# calc5_target_db register map
Vendor: Texas Instruments
Address unit: 16 bits
Registers are 32-bit, read-write, reset 0x0 unless marked. A register's access mark holds for its fields unless they carry their own. Offsets are as the file gives them; [hi:lo] are bit positions; {n}, {i} and the like mark numbered series; 'fields as' and 'values as' point back to an identical list; <NAME> marks a mode.

## DSS (part 2 of 4) — ipxact12_to_ccs_generated
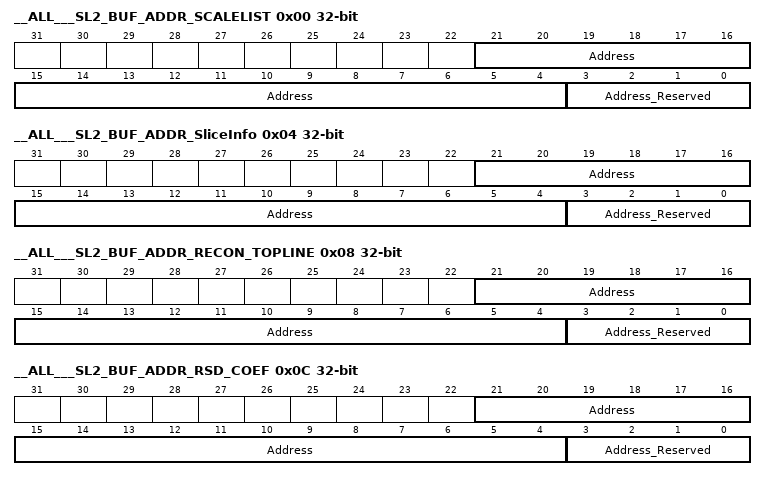
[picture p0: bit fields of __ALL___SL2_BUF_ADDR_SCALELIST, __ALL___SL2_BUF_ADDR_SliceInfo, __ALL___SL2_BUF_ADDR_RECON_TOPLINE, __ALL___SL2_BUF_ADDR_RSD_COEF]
0x00 __ALL___SL2_BUF_ADDR_SCALELIST access per field — Start Address for Scalling List Matrix same as "weight Matrix" in CALC3 (Required only in High-Profile, else don't care)
  [21:4] Address rw — 128-bit (16-byte) aligned address
  [3:0] Address_Reserved ro — Address is 128-bit (16*BitDepth) aligned
0x04 __ALL___SL2_BUF_ADDR_SliceInfo access per field
  fields as __ALL___SL2_BUF_ADDR_SCALELIST
0x08 __ALL___SL2_BUF_ADDR_RECON_TOPLINE access per field
  fields as __ALL___SL2_BUF_ADDR_SCALELIST
0x0C __ALL___SL2_BUF_ADDR_RSD_COEF access per field
  fields as __ALL___SL2_BUF_ADDR_SCALELIST
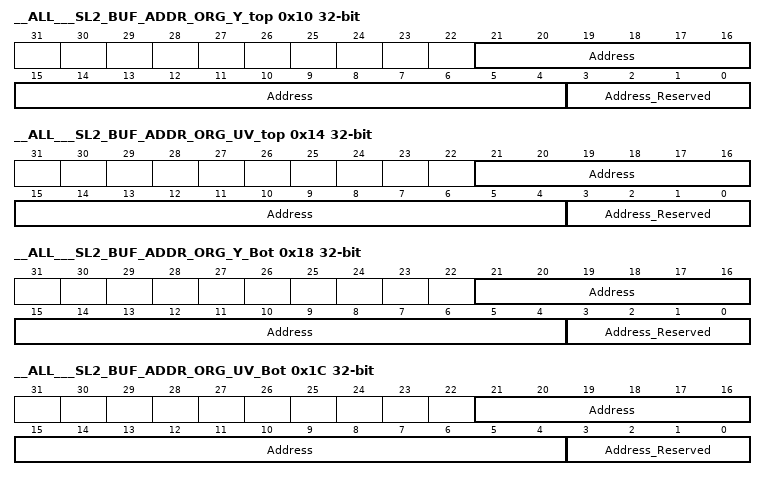
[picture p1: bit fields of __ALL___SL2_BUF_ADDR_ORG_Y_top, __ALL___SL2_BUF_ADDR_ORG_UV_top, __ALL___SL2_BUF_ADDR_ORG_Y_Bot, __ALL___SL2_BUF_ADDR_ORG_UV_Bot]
0x10 __ALL___SL2_BUF_ADDR_ORG_Y_top access per field
  fields as __ALL___SL2_BUF_ADDR_SCALELIST
0x14 __ALL___SL2_BUF_ADDR_ORG_UV_top access per field
  fields as __ALL___SL2_BUF_ADDR_SCALELIST
0x18 __ALL___SL2_BUF_ADDR_ORG_Y_Bot access per field
  fields as __ALL___SL2_BUF_ADDR_SCALELIST
0x1C __ALL___SL2_BUF_ADDR_ORG_UV_Bot access per field
  fields as __ALL___SL2_BUF_ADDR_SCALELIST
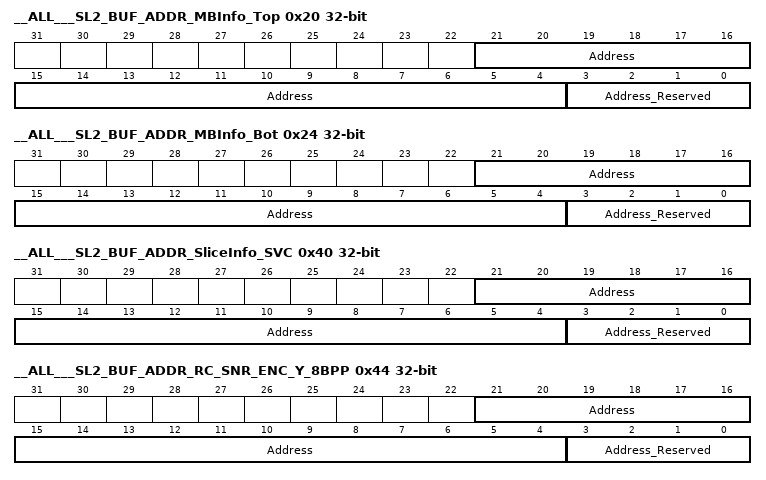
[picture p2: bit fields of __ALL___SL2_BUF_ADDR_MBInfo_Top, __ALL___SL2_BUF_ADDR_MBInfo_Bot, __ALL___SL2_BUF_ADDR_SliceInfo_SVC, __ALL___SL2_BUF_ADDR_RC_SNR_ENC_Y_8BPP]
0x20 __ALL___SL2_BUF_ADDR_MBInfo_Top access per field
  fields as __ALL___SL2_BUF_ADDR_SCALELIST
0x24 __ALL___SL2_BUF_ADDR_MBInfo_Bot access per field
  fields as __ALL___SL2_BUF_ADDR_SCALELIST
0x40 __ALL___SL2_BUF_ADDR_SliceInfo_SVC access per field — SL2 BA of SVC Extrension of Slice Info
  fields as __ALL___SL2_BUF_ADDR_SCALELIST
0x44 __ALL___SL2_BUF_ADDR_RC_SNR_ENC_Y_8BPP access per field — SL2 base address for rc luma 8bpp output for me5 from calc5
  fields as __ALL___SL2_BUF_ADDR_SCALELIST
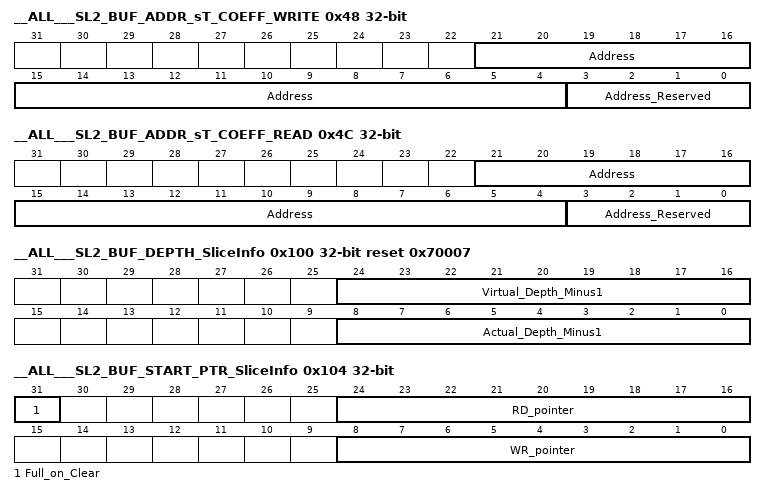
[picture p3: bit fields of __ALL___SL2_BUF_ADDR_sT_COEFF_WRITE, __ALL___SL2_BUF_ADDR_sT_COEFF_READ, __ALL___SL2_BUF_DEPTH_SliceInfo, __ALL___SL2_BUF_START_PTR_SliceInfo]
0x48 __ALL___SL2_BUF_ADDR_sT_COEFF_WRITE access per field — SL2 base address for stcoeff output from calc5
  fields as __ALL___SL2_BUF_ADDR_SCALELIST
0x4C __ALL___SL2_BUF_ADDR_sT_COEFF_READ access per field — SL2 base address for stcoeff input to calc5
  fields as __ALL___SL2_BUF_ADDR_SCALELIST
0x100 __ALL___SL2_BUF_DEPTH_SliceInfo access per field reset 0x70007 — Configures the SLiceInfo Buffer depth.
  [24:16] Virtual_Depth_Minus1 rw — Indicates the Maximum pointer difference. Virtual buffer depth < Actual buffer depth. When the pointer difference is more than the configured value the wr_bc_ready gets de-asserted.
  [8:0] Actual_Depth_Minus1 rw — Number of entries in the Buffer = 1 + Actual_buffer_depth_minus1
0x104 __ALL___SL2_BUF_START_PTR_SliceInfo access per field — Configures the Slice_Info Buffer pointers.
  [31] Full_on_Clear rw — if (WR_pointer == RD_pointer) [0] : buffer is empty [1] : buffer is full
  [24:16] RD_pointer rw — Start value of Read pointer, initialized on BC_CLR. Range: 0 to Actual_buffer_depth_minus1
  [8:0] WR_pointer rw — Start value of Write pointer, initialized on BC_CLR. Range: 0 to Actual_buffer_depth_minus1
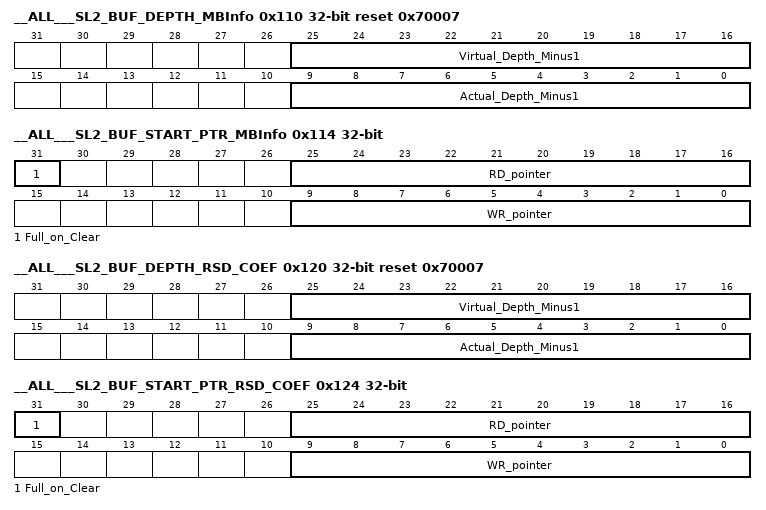
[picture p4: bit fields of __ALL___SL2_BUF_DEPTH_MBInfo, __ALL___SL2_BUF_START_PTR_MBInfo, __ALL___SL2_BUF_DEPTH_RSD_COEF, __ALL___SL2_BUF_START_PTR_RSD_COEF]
0x110 __ALL___SL2_BUF_DEPTH_MBInfo access per field reset 0x70007 — Configures the MBInfo Buffer depth.
  [25:16] Virtual_Depth_Minus1 rw — Indicates the Maximum pointer difference. Virtual buffer depth < Actual buffer depth. When the pointer difference is more than the configured value the wr_bc_ready gets de-asserted.
  [9:0] Actual_Depth_Minus1 rw — Number of entries in the Buffer = 1 + Actual_buffer_depth_minus1
0x114 __ALL___SL2_BUF_START_PTR_MBInfo access per field — Configures the MB-Info Buffer pointers.
  [31] Full_on_Clear rw — if (WR_pointer == RD_pointer) [0] : buffer is empty [1] : buffer is full
  [25:16] RD_pointer rw — Start value of Read pointer, initialized on BC_CLR. Range: 0 to Actual_buffer_depth_minus1
  [9:0] WR_pointer rw — Start value of Write pointer, initialized on BC_CLR. Range: 0 to Actual_buffer_depth_minus1
0x120 __ALL___SL2_BUF_DEPTH_RSD_COEF access per field reset 0x70007 — Configures the Residue Buffer depth.
  fields as __ALL___SL2_BUF_DEPTH_MBInfo
0x124 __ALL___SL2_BUF_START_PTR_RSD_COEF access per field — Configures the Residual Buffer pointers.
  fields as __ALL___SL2_BUF_START_PTR_MBInfo
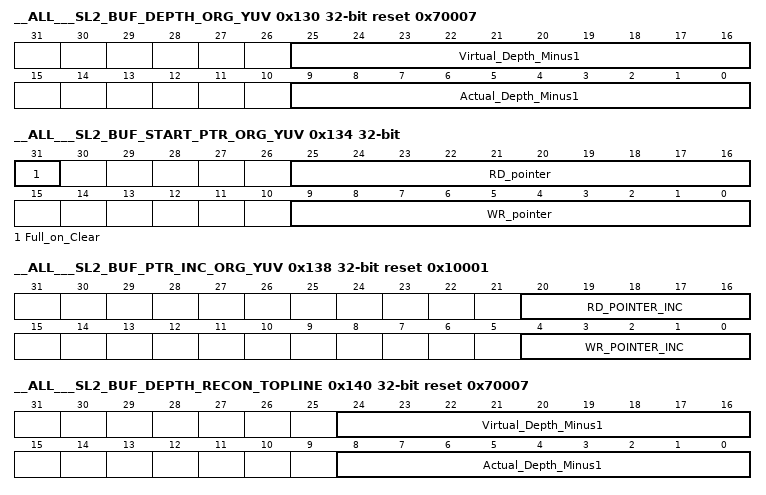
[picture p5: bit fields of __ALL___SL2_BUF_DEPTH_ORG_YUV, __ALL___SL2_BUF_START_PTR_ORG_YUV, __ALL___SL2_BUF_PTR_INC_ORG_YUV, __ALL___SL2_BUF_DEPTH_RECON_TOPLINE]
0x130 __ALL___SL2_BUF_DEPTH_ORG_YUV access per field reset 0x70007 — Configures the Original Buffer depth.
  fields as __ALL___SL2_BUF_DEPTH_MBInfo
0x134 __ALL___SL2_BUF_START_PTR_ORG_YUV access per field — Configures the Original Buffer pointers.
  fields as __ALL___SL2_BUF_START_PTR_MBInfo
0x138 __ALL___SL2_BUF_PTR_INC_ORG_YUV access per field reset 0x10001 — Configures the increment offset for buffer pointers.
  [20:16] RD_POINTER_INC ro
  [4:0] WR_POINTER_INC rw — Increment value for write pointer on wr_core_busy deassertion. Range: 0 to Actual_buffer_depth_minus1
0x140 __ALL___SL2_BUF_DEPTH_RECON_TOPLINE access per field reset 0x70007 — Configures the RefPix Buffer depth.
  fields as __ALL___SL2_BUF_DEPTH_SliceInfo
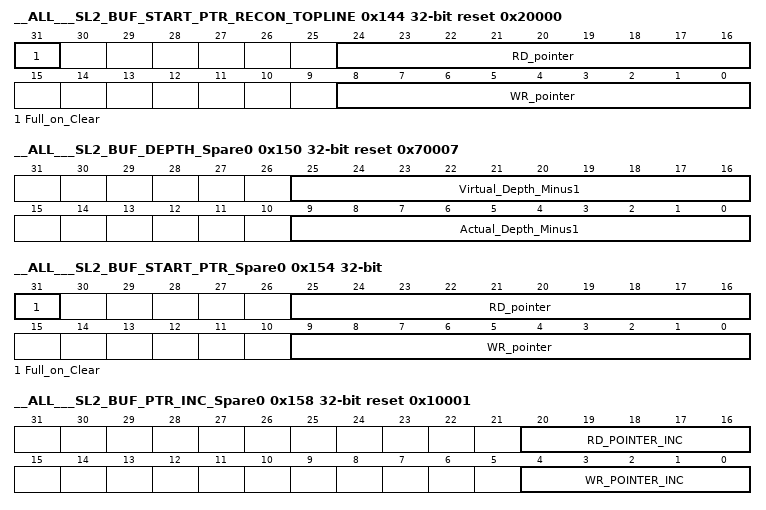
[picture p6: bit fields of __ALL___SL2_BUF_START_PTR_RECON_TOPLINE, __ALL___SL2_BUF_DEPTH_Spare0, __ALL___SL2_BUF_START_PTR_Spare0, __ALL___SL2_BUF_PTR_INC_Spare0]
0x144 __ALL___SL2_BUF_START_PTR_RECON_TOPLINE access per field reset 0x20000 — Configures the RefPix Buffer pointers.
  fields as __ALL___SL2_BUF_START_PTR_SliceInfo
0x150 __ALL___SL2_BUF_DEPTH_Spare0 access per field reset 0x70007 — Control from iCONT
  fields as __ALL___SL2_BUF_DEPTH_MBInfo
0x154 __ALL___SL2_BUF_START_PTR_Spare0 access per field — Control from iCONT
  fields as __ALL___SL2_BUF_START_PTR_MBInfo
0x158 __ALL___SL2_BUF_PTR_INC_Spare0 access per field reset 0x10001 — Control from iCONT
  fields as __ALL___SL2_BUF_PTR_INC_ORG_YUV
0x15C __ALL___SL2_BUF_RD_THRESHOLD_Spare0 access per field — Control from iCONT
  [9:0] RD_THRESHOLD rw — bc_ready for the read side is asserted only if the number of filled BUFFER_ENTRYs is more than or equal to the rd_threshold. rd_threshold >= rd_pointer_inc
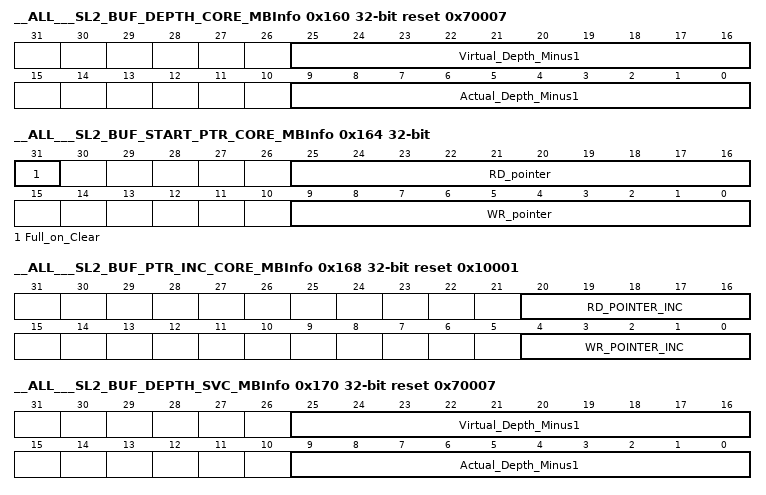
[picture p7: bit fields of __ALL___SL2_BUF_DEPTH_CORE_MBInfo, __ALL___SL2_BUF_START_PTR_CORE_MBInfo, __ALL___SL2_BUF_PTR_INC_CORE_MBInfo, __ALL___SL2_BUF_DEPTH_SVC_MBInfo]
0x160 __ALL___SL2_BUF_DEPTH_CORE_MBInfo access per field reset 0x70007 — Configures the calc5 modified MB-Info Buffer's depths in SVC to write out the header part into DDR
  fields as __ALL___SL2_BUF_DEPTH_MBInfo
0x164 __ALL___SL2_BUF_START_PTR_CORE_MBInfo access per field — Configures the calc5 modified MB-Info Buffer's pointers in SVC to write out the header part into DDR
  fields as __ALL___SL2_BUF_START_PTR_MBInfo
0x168 __ALL___SL2_BUF_PTR_INC_CORE_MBInfo access per field reset 0x10001 — Configures the calc5 modified MB-Info Buffer's increment offset for buffer pointers in SVC to write out the header part into DDR
  fields as __ALL___SL2_BUF_PTR_INC_ORG_YUV
0x170 __ALL___SL2_BUF_DEPTH_SVC_MBInfo access per field reset 0x70007 — Configures the MB-Info Buffer depths in SVC to write out the header part into DDR this buffer is between ME and CALC5 DRM
  fields as __ALL___SL2_BUF_DEPTH_MBInfo
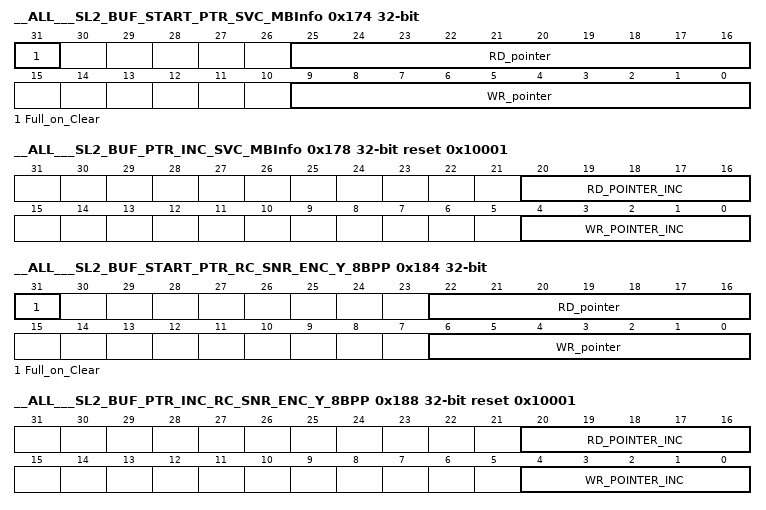
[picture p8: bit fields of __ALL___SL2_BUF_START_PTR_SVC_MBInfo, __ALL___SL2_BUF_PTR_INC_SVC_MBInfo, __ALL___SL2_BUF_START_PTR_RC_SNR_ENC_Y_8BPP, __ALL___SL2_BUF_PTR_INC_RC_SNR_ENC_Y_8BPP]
0x174 __ALL___SL2_BUF_START_PTR_SVC_MBInfo access per field — Configures the MB-Info Buffer pointers in SVC to write out the header part into DDR this buffer is between ME and CALC5 DRM
  fields as __ALL___SL2_BUF_START_PTR_MBInfo
0x178 __ALL___SL2_BUF_PTR_INC_SVC_MBInfo access per field reset 0x10001 — Configures the MB-Info Buffer's pointers in SVC to write out the header part into DDR this buffer is between ME and CALC5 DRM
  fields as __ALL___SL2_BUF_PTR_INC_ORG_YUV
0x17C __ALL___SL2_BUF_RD_THRESHOLD_SVC_MBInfo access per field — Configures the MB-Info Buffer's read threshold in SVC to write out the header part into DDR this buffer is between ME and CALC5 DRM
  fields as __ALL___SL2_BUF_RD_THRESHOLD_Spare0
0x180 __ALL___SL2_BUF_DEPTH_RC_SNR_ENC_Y_8BPP access per field reset 0x7 — Configures the Luma data Buffer's pointers in SVC to write out this into DDR to be used by ME5 in next layer.
  [6:0] Actual_Depth_Minus1 rw — Number of entries in the Buffer = 1 + Actual_buffer_depth_minus1
0x184 __ALL___SL2_BUF_START_PTR_RC_SNR_ENC_Y_8BPP access per field — Configures the Luma data Buffer's start pointers in SVC to write out this into DDR to be used by ME5 in next layer.
  [31] Full_on_Clear rw — if (WR_pointer == RD_pointer) [0] : buffer is empty [1] : buffer is full
  [22:16] RD_pointer rw — Start value of Read pointer, initialized on BC_CLR. Range: 0 to Actual_buffer_depth_minus1
  [6:0] WR_pointer rw — Start value of Write pointer, initialized on BC_CLR. Range: 0 to Actual_buffer_depth_minus1
0x188 __ALL___SL2_BUF_PTR_INC_RC_SNR_ENC_Y_8BPP access per field reset 0x10001 — Configures the Luma data Buffer's increment offset for buffer pointersin SVC to write out this into DDR to be used by ME5 in next layer.
  [20:16] RD_POINTER_INC rw
  [4:0] WR_POINTER_INC ro — Increment value for write pointer on wr_core_busy deassertion. Range: 0 to Actual_buffer_depth_minus1
0x18C __ALL___SL2_BUF_RD_THRESHOLD_RC_SNR_ENC_Y_8BPP access per field — Configures the Luma data Buffer's read threshold in SVC to write out this into DDR to be used by ME5 in next layer.
  fields as __ALL___SL2_BUF_RD_THRESHOLD_Spare0
0x190 __ALL___SL2_BUF_DEPTH_WRITE_sT_COEFF access per field reset 0x7 — Configures the stcoeff data (Produced by CALC in SVC for next layer) Buffer's depth in SVC to write out this into DDR to be used by ME5 in next layer.
  fields as __ALL___SL2_BUF_DEPTH_RC_SNR_ENC_Y_8BPP
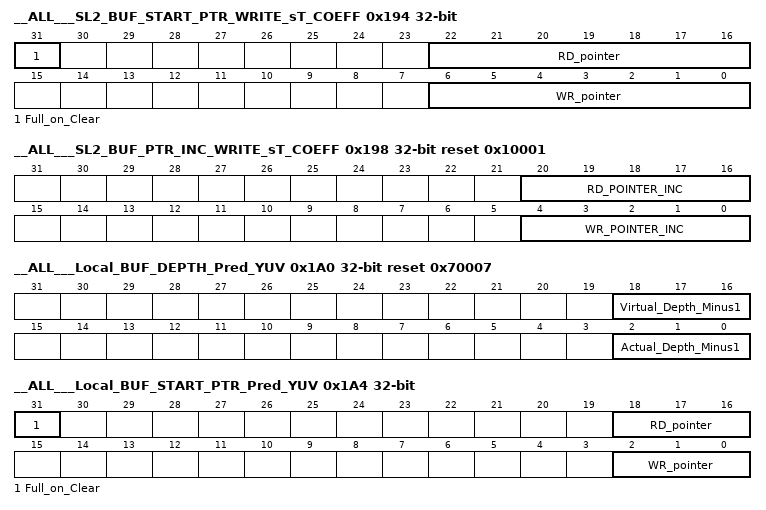
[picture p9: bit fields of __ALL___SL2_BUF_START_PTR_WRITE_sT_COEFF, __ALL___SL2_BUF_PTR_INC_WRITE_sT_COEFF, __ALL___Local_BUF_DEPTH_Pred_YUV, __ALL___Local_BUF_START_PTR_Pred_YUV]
0x194 __ALL___SL2_BUF_START_PTR_WRITE_sT_COEFF access per field — Configures the stcoeff data (Produced by CALC in SVC for next layer) Buffer's start pointer in SVC to write out this into DDR to be used by ME5 in next layer.
  fields as __ALL___SL2_BUF_START_PTR_RC_SNR_ENC_Y_8BPP
0x198 __ALL___SL2_BUF_PTR_INC_WRITE_sT_COEFF access per field reset 0x10001 — Configures the stcoeff data (Produced by CALC in SVC for next layer) Buffer's pointer increment in SVC to write out this into DDR to be used by ME5 in next layer.
  fields as __ALL___SL2_BUF_PTR_INC_RC_SNR_ENC_Y_8BPP
0x19C __ALL___SL2_BUF_RD_THRESHOLD_WRITE_sT_COEFF access per field — Configures the stcoeff data (Produced by CALC in SVC for next layer) Buffer's read threshold in SVC to write out this into DDR to be used by ME5 in next layer.
  fields as __ALL___SL2_BUF_RD_THRESHOLD_Spare0
0x1A0 __ALL___Local_BUF_DEPTH_Pred_YUV access per field reset 0x70007 — Configures the Pred Buffer depths.
  [18:16] Virtual_Depth_Minus1 rw — Indicates the Maximum pointer difference. Virtual buffer depth < Actual buffer depth. When the pointer difference is more than the configured value the wr_bc_ready gets de-asserted.
  [2:0] Actual_Depth_Minus1 rw — Number of entries in the Buffer = 1 + Actual_buffer_depth_minus1
0x1A4 __ALL___Local_BUF_START_PTR_Pred_YUV access per field — Configures the Pred Buffer pointers.
  [31] Full_on_Clear rw — if (WR_pointer == RD_pointer) [0] : buffer is empty [1] : buffer is full
  [18:16] RD_pointer rw — Start value of Read pointer, initialized on BC_CLR. Range: 0 to Actual_buffer_depth_minus1
  [2:0] WR_pointer rw — Start value of Write pointer, initialized on BC_CLR. Range: 0 to Actual_buffer_depth_minus1
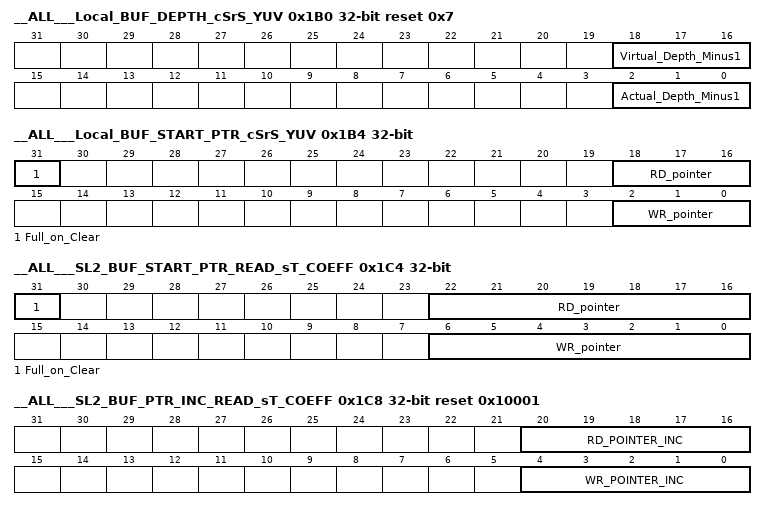
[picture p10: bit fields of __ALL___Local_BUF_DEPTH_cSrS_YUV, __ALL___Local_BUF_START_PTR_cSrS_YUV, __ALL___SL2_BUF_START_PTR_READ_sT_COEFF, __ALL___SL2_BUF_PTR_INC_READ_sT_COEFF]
0x1B0 __ALL___Local_BUF_DEPTH_cSrS_YUV access per field reset 0x7 — Configures the rS/cS Buffer pointers.
  [18:16] Virtual_Depth_Minus1 ro — Indicates the Maximum pointer difference. Virtual buffer depth < Actual buffer depth. When the pointer difference is more than the configured value the wr_bc_ready gets de-asserted.
  [2:0] Actual_Depth_Minus1 rw — Number of entries in the Buffer = 1 + Actual_buffer_depth_minus1
0x1B4 __ALL___Local_BUF_START_PTR_cSrS_YUV access per field — Configures the rS/cS Buffer pointers.
  fields as __ALL___Local_BUF_START_PTR_Pred_YUV
0x1C0 __ALL___SL2_BUF_DEPTH_READ_sT_COEFF access per field reset 0x7 — Configures the stcoeff data (Consumed by SVC from Previous layer) Buffer's depth in SVC to write out this into DDR to be used by ME5 in next layer.
  fields as __ALL___SL2_BUF_DEPTH_RC_SNR_ENC_Y_8BPP
0x1C4 __ALL___SL2_BUF_START_PTR_READ_sT_COEFF access per field — Configures the stcoeff data (Consumed by SVC from Previous layer) Buffer's start pointer in SVC to write out this into DDR to be used by ME5 in next layer.
  fields as __ALL___SL2_BUF_START_PTR_RC_SNR_ENC_Y_8BPP
0x1C8 __ALL___SL2_BUF_PTR_INC_READ_sT_COEFF access per field reset 0x10001 — Configures the stcoeff data (Consumed by SVC from Previous layer) Buffer's pointer increment in SVC to write out this into DDR to be used by ME5 in next layer.
  fields as __ALL___SL2_BUF_PTR_INC_RC_SNR_ENC_Y_8BPP
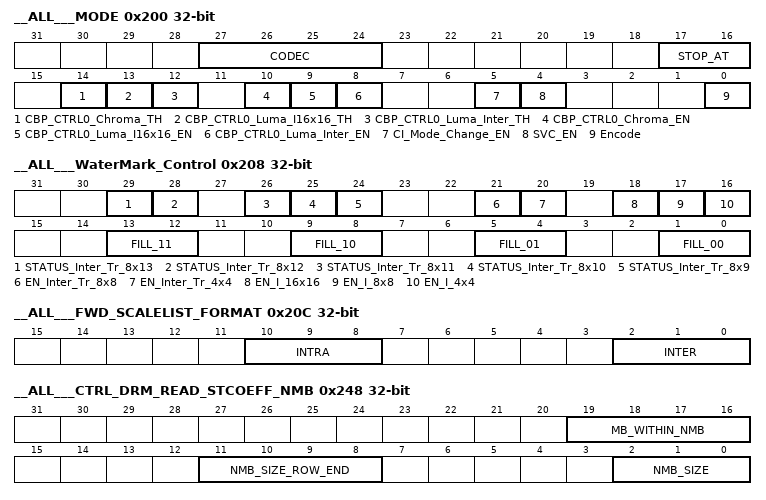
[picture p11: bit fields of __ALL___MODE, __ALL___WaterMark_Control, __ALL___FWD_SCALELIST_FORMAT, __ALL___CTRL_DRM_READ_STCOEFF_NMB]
0x200 __ALL___MODE access per field — CALC3 mode select register
  [27:24] CODEC ro — [0] H.264 [other] : Reserved
  [17:16] STOP_AT ro — CALC5_EN bit will be cleared and interupt is generated Stop Calc @ [0] : Pipe-Down [1] : Slice End [2] : End-of-Row [3] : MB-Done
  [14] CBP_CTRL0_Chroma_TH rw — # of abs ones coeffs threshold for CBP_CTRL0_CHROMA_EN It is effective for CBP_CTRL0_CHRO_EN = 1 [0] : threshold_2 = 1 [1] : threshold_2 = 2
  [13] CBP_CTRL0_Luma_I16x16_TH rw — # of abs ones coeffs threshold for CBP_CTRL0_LUMA_I16x16_EN It is effective for CBP_CTRL0_LUMA_I16x16_EN = 1 [0] : threshold_1 = 1 [1] : threshold_1 = 2
  [12] CBP_CTRL0_Luma_Inter_TH rw — # of abs ones coeffs threshold for CBP_CTRL0_LUMA_INTER_EN It is effective for CBP_CTRL0_LUMA_INTER_EN = 1 [0] : threshold_0 = 1 [1] : threshold_0 = 2
  [10] CBP_CTRL0_Chroma_EN rw — CBPControl #0 enable flag for Chroma DC Trans mode [0] : disable [1] : enable It is effective for enc and DC transform used in Cb and Cr blocks. When DcTransform is effective for Cb/Cr and this flag = 1, if all the non-zero coeffs among quantized 60 AC coeffs (w/o 4DC coeffs) in the 8x8 block are one in abs domain and the number of ones coeffs is less than threshold_2, this corresponded CBP sets to zero, , where threshold_2 = CALC_CBPCNT0_CHRO_DCTRANS_THR + 1. Its threshold of threshold_2 is set in the CALC_CBPCNT0_CHRO_DCTRANS_THR register. Note that the abs one coefficients are not turns to zero in the residual data, the CBP is only controlled to zero.
  [9] CBP_CTRL0_Luma_I16x16_EN rw — CBPControl #0 enable flag for Luma DC Trans mode [0] : disable [1] : enable It is effective for enc and DC transform used in Luma 16x16 block. When DcTransform is effective for Luma and this flag = 1, if all the non-zero coeffs among quantized 60 AC coeffs (w/o 4DC coeffs) in an 8x8 luma block are one in abs domain and the number of ones coeffs is less than threshold_1, this corresponded CBP sets to zero, where threshold_1 = CALC_CBPCNT0_LUMA_DCTRANS_THR + 1. Its threshold of threshold_1 can be set in the CBP_CTRL0_LUMA_I16x16_TH register. Note that the abs one coefficients are not turns to zero in the residual data, the CBP is only controlled to zero.
  [8] CBP_CTRL0_Luma_Inter_EN rw — CBPControl #0 enable flag for Inter Block [0] : disable [1] : enable It is effective for enc only. For an 8x8 block (w/o DcTransform) and its block of inter, if all the non-zero coeffs among quantized 64 coeffs are less than one in abs domain and the number of the ones coeffs <= threshold_0, this corresponded CBP sets to zero, where threshold_0 = CALC_CBPCNT0_INTER_THR + 1. Its threshold of threshold_0 can be set in the CBP_CTRL0_INTER_TH register. Note that the abs one coefficients does not turn to zero in the residual data, the CBP is only controlled to zero.
  [5] CI_Mode_Change_EN rw — Enable Left block Intra-Mode change in Constraint-Intra-Predication (Only in Encode) [1] : mode-change enable [0] : mode-change diable
  [4] SVC_EN rw — Enable SVC [0] : Disable SVC [1] : Enable SVC
  [0] Encode rw — Enc or Dec mode flag [0] : Dec [1] : Enc Note that a part of codecs is supported only for dec. RealVideo, VP6/7, H.263 AnnexI mode are supported only for dec. Enc mode is reserved for them.
0x208 __ALL___WaterMark_Control access per field — Detail of this register shoudl not be made Public. "This is TI Confidencial data" Only for TI internal USE
  [29] STATUS_Inter_Tr_8x13 ro — Status of Watermark in DECODE
  [28] STATUS_Inter_Tr_8x12 ro — Status of Watermark in DECODE
  [26] STATUS_Inter_Tr_8x11 ro — Status of Watermark in DECODE
  [25] STATUS_Inter_Tr_8x10 ro — Status of Watermark in DECODE
  [24] STATUS_Inter_Tr_8x9 ro — Status of Watermark in DECODE
  [21] EN_Inter_Tr_8x8 ro — Watermark Watermark to Inter with 8x8 Transform
  [20] EN_Inter_Tr_4x4 ro — Watermark to Inter with 4x4 Transform
  [18] EN_I_16x16 rw — Add Watermark to Intra_16x16 MB
  [17] EN_I_8x8 rw — Add Watermark to Intra_8x8 MB
  [16] EN_I_4x4 rw — Add Watermark to Intra_4x4 MB
  [13:12] FILL_11 rw — 2-bit SIGNED value
  [9:8] FILL_10 rw — 2-bit SIGNED value
  [5:4] FILL_01 rw — 2-bit SIGNED value
  [1:0] FILL_00 rw — 2-bit SIGNED value
0x20C __ALL___FWD_SCALELIST_FORMAT access per field
  [10:8] INTRA rw — Intra weightScaling format (2's Compliment) [0] : 2Q14 (Default) Format = {2+INTRA}Q{14-INTRA}
  [2:0] INTER rw — Inter weightScaling format (2's Compliment) [0] : 2Q14 (Default) Format = {2+INTER}Q{14-INTER}
0x210 __ALL___FWDQ_RND_INTRA_AC access per field reset 0x2AAAAA80 — CALC5 forward quantiation's rounding coefficients
  [30:7] Q_RND_COEF rw — Forward quantiation's rounding coefficients for intra MB. Hence, for intra MB and fwdQ, Round Coefficient AC[0] = this bit field by command wrapper (Signed 25-bit).
0x214 __ALL___FWDQ_RND_INTER_AC access per field reset 0x15555500 — CALC5 forward quantiation's rounding coefficients
  [30:7] Q_RND_COEF rw — Forward quantiation's rounding coefficients for inter MB. Hence, for inter MB and fwdQ, Round Coefficient AC[0] = this bit field by command wrapper (Table 22/23) (Signed 25-bit).
0x218 __ALL___FWDQ_RND_INTRA_DC access per field reset 0x2AAAAA80 — Round offset value setting for fwd Q, intra and DC coefficient.
  [30:7] Q_RND_COEF rw — Forward quantiation's rounding coefficients for intra MB and its DC coefficients. Hence, for intra MB, fwdQ and DC coefficients, FwdQ uses it as its rounding coefficient. Fwd Round Coefficient DC[0] = this bit field by command wrapper(Table. 21/22)(Signed 25-bit).
0x21C __ALL___FWDQ_RND_INTER_DC access per field reset 0x15555500 — Round offset value setting for fwd Q, inter and DC coefficient.
  [30:7] Q_RND_COEF rw — Forward quantiation's rounding coefficients for inter MB and its DC coefficients. Hence, for inter MB, fwdQ and DC coefficients, FwdQ uses it as its rounding coefficient. Round Coefficient DC[0] = this bit field (Table. 21/22) (Signed 25-bit).
0x240 __ALL___CTRL_SVC_WRITE_MBHDRINFO access per field — Register to control MBInfo write in SVC Enc
  [5:0] GROUP_ID rw — Group ID for vDMA Transfer
0x244 __ALL___CTRL_DRM_RC_SNR_ENC_Y_8BPP access per field — Register to control RC Luma data write in SVC SNR Enc
  [5:0] GROUP_ID rw — Group ID for vDMA Transfer
0x248 __ALL___CTRL_DRM_READ_STCOEFF_NMB access per field — Register to control NMB info for stcoeff data read in SVC SNR Enc
  [19:16] MB_WITHIN_NMB rw — Indicates the position of the current MBs being read by the core from SL2 within a n-MB. The valid values are 0 to N-1, where 0 is the default value. This field is used by the core to create read busy to the BC. This should be updated in rewind based on the position of the MB from which new slice starts.
  [11:8] NMB_SIZE_ROW_END rw — Indicates the number of MBs fetched by VDMA for the last trigger in row. The valid values are 0 to N-1, where 0 is the default value
  [2:0] NMB_SIZE rw — Indicates the number of MBs fetched by VDMA per trigger for non end of row triggers. The valid values are 1,2,4,8 and 16, where 1 is the default value. The encoding is: 0 => 1 MB 1 => 2MB 2 => 4MB 3 => 8MB 4 => 16MB 5-7 => Reserved
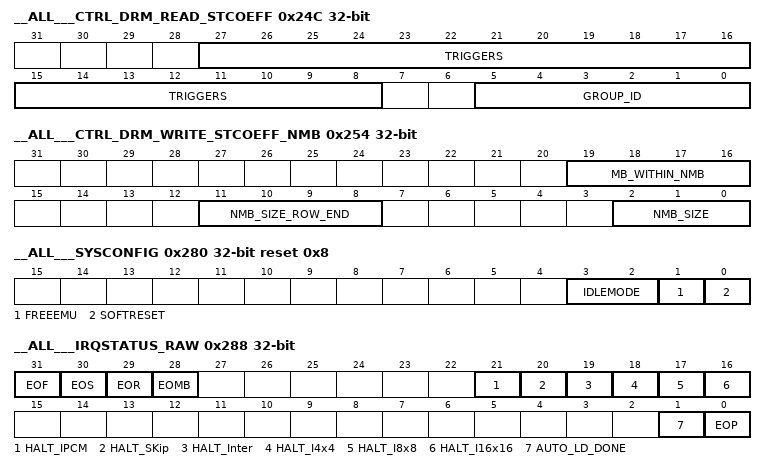
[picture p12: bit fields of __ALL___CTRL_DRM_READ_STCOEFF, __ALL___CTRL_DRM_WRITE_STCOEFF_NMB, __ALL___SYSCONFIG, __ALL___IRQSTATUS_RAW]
0x24C __ALL___CTRL_DRM_READ_STCOEFF access per field — Register to control stcoeff data read in SVC SNR Enc
  [27:8] TRIGGERS rw — Indicates the number of triggers needed to complete the fetching of one complete picture
  [5:0] GROUP_ID rw — Group ID for vDMA Transfer
0x250 __ALL___CTRL_DRM_READ_STCOEFF_STATUS access per field — Indicates the number of read transfers that are triggers (status)
  [19:0] READ_TRIGGERED rw — Indicates the number of read transfers that are triggers
0x254 __ALL___CTRL_DRM_WRITE_STCOEFF_NMB access per field — Register to control nmb info for stcoeff data write in SVC SNR Enc
  [19:16] MB_WITHIN_NMB rw — Indicates the position of the current MBs being written by the core into SL2 within a n-MB. The valid values are 0 to N-1, where 0 is the default value. This field is used by the core to create write busy to the BC. This should be updated in rewind based on the position of the MB from which new slice starts.
  [11:8] NMB_SIZE_ROW_END rw — Indicates the number of MBs written by VDMA for the last trigger in row. The valid values are 0 to N-1, where 0 is the default value
  [2:0] NMB_SIZE rw — Indicates the number of MBs written by VDMA per trigger for non end of row triggers. The valid values are 1,2,4,8 and 16, where 1 is the default value. The encoding is: 0 => 1 MB 1 => 2MB 2 => 4MB 3 => 8MB 4 => 16MB 5-7 => Reserved
0x258 __ALL___CTRL_DRM_WRITE_STCOEFF access per field — Register to control stcoeff data write in SVC SNR Enc
  [5:0] GROUP_ID rw — Group ID for vDMA Transfer
0x280 __ALL___SYSCONFIG access per field reset 0x8 — Clock management configuration
  [3:2] IDLEMODE rw — Configuration of the local target state management mode. By definition, target can handle read/write transaction as long as it is out of IDLE state. 0: Force-idle mode: local target's idle state follows (acknowledges) the system's idle requests unconditionally, i.e. regardless of the IP module's internal requirements. Backup mode, for debug only. 1: No-idle mode: local target never enters idle state. Backup mode, for debug only. 2: Smart-idle mode: local target's idle state eventually follows (acknowledges) the system's idle requests, depending on the IP module's internal requirements. IP module shall not generate (IRQ- or DMA-request-related) wakeup events. 3: Smart-idle wakeup-capable mode: local target's idle state eventually follows (acknowledges) the system's idle requests, depending on the IP module's internal requirements. IP module may generate (IRQ- or DMA-request-related) wakeup events when in idle state. Mode is only relevant if the appropriate IP module "swakeup" output(s) is (are) implemented.
  [1] FREEEMU rw — Sensitivity to emulation (debug) suspend input signal. 0: IP module is sensitive to emulation suspend 1: IP module is not sensitive to emulation suspend
  [0] SOFTRESET rw — Software reset Read0: Reset done, no pending action Read1: Reset (software or other) on going Write0: No action Write1: Initiate software reset
0x288 __ALL___IRQSTATUS_RAW access per field — Per-event raw interrupt status vector. Raw status is set even if event is not enabled. Write 1 to set the (raw) status, mostly for debug.
  [31] EOF rw — settable raw status for END-OF-FRAME Interupt. Write 0: No action Read 0: No event pending Read 1: Event pending Write 1: Set event (debug)
  [30] EOS rw — settable raw status for END-OF-SLICE Interupt. Write 0: No action Read 0: No event pending Read 1: Event pending Write 1: Set event (debug)
  [29] EOR rw — settable raw status for END-OF-ROW Interupt. Write 0: No action Read 0: No event pending Read 1: Event pending Write 1: Set event (debug)
  [28] EOMB rw — settable raw status for END-OF-MB Interupt. Write 0: No action Read 0: No event pending Read 1: Event pending Write 1: Set event (debug)
  [21] HALT_IPCM ro — settable raw status for HALT_ON_IPCM Interupt. Write : No action Read 0: No event pending Read 1: Event pending
  [20] HALT_SKip ro — settable raw status for HALT_ON_SKIP Interupt. Write 0: No action Read 0: No event pending Read 1: Event pending Write 1: Set event (debug)
  [19] HALT_Inter ro — settable raw status for HALT_ON_I_Inter (non Skip) Interupt. Write 0: No action Read 0: No event pending Read 1: Event pending Write 1: Set event (debug)
  [18] HALT_I4x4 ro — settable raw status for HALT_ON_I_4x4 Interupt. Write 0: No action Read 0: No event pending Read 1: Event pending Write 1: Set event (debug)
  [17] HALT_I8x8 ro — settable raw status for HALT_ON_I_8x8 Interupt. Write 0: No action Read 0: No event pending Read 1: Event pending Write 1: Set event (debug)
  [16] HALT_I16x16 ro — settable raw status for HALT_ON_I_16x16 Interupt. Write 0: No action Read 0: No event pending Read 1: Event pending Write 1: Set event (debug)
  [1] AUTO_LD_DONE ro — settable raw status for AUTO_LD_DONE Interupt. Write 0: No action Read 0: No event pending Read 1: Event pending Write 1: Set event (debug)
  [0] EOP ro — settable raw status for END-OF-PIPE Interupt. Write 0: No action Read 0: No event pending Read 1: Event pending Write 1: Set event (debug)
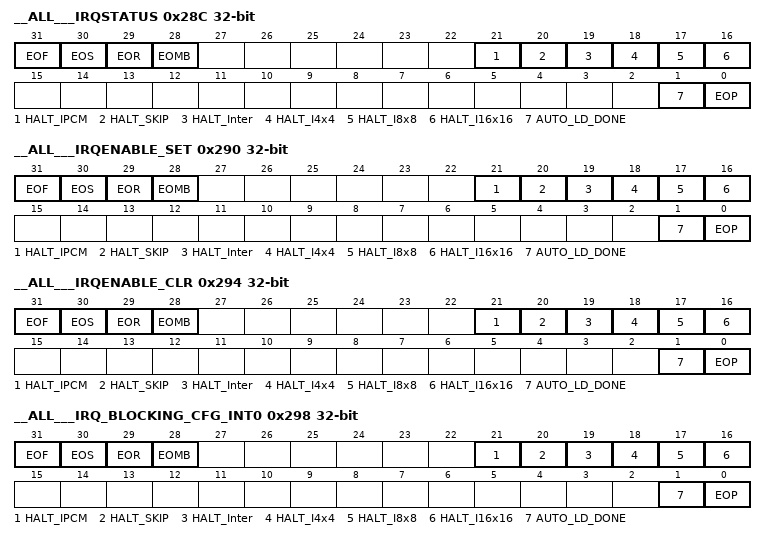
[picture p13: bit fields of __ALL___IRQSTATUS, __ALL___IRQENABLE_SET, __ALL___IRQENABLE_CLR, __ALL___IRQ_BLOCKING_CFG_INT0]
0x28C __ALL___IRQSTATUS access per field — Per-event "enabled" interrupt status vector. Enabled status isn't set unless event is enabled. Write 1 to clear the status after interrupt has been serviced (raw status gets cleared, i.e. even if not enabled).
  [31] EOF rw — clearable, enabled status for END-OF-FRAME Interrupt. Write 0: No action Read 0: No (enabled) event pending Read 1: Event pending Write 1: Clear (raw) event
  [30] EOS rw — clearable, enabled status for END-OF-SLICE Interrupt. Write 0: No action Read 0: No (enabled) event pending Read 1: Event pending Write 1: Clear (raw) event
  [29] EOR rw — clearable, enabled status for END-OF-ROW Interrupt. Write 0: No action Read 0: No (enabled) event pending Read 1: Event pending Write 1: Clear (raw) event
  [28] EOMB rw — clearable, enabled status for End-OF-MB Interrupt. Write 0: No action Read 0: No (enabled) event pending Read 1: Event pending Write 1: Clear (raw) event
  [21] HALT_IPCM rw — clearable, enabled status for HALT_ON_IPCM Interrupt. Write 0: No action Read 0: No (enabled) event pending Read 1: Event pending Write 1: Clear (raw) event
  [20] HALT_SKIP rw — learable, enabled status for HALT_ON_SKIP Interrupt. Write 0: No action Read 0: No (enabled) event pending Read 1: Event pending Write 1: Clear (raw) event
  [19] HALT_Inter rw — clearable, enabled status for HALT_ON_Inter Interrupt. Write 0: No action Read 0: No (enabled) event pending Read 1: Event pending Write 1: Clear (raw) event
  [18] HALT_I4x4 rw — clearable, enabled status for HALT_ON_I4x4 Interrupt. Write 0: No action Read 0: No (enabled) event pending Read 1: Event pending Write 1: Clear (raw) event
  [17] HALT_I8x8 rw — clearable, enabled status for HALT_ON_I8x8 Interrupt. Write 0: No action Read 0: No (enabled) event pending Read 1: Event pending Write 1: Clear (raw) event
  [16] HALT_I16x16 rw — I16x16clearable, enabled status for HALT_ON_I16x16 Interrupt. Write 0: No action Read 0: No (enabled) event pending Read 1: Event pending Write 1: Clear (raw) event
  [1] AUTO_LD_DONE ro — clearable, enabled status for AUTO_LD_DONE Interrupt. Write 0: No action Read 0: No (enabled) event pending Read 1: Event pending Write 1: Clear (raw) event
  [0] EOP ro — clearable, enabled status for End of Pipe Interrupt. Write 0: No action Read 0: No (enabled) event pending Read 1: Event pending Write 1: Clear (raw) event
0x290 __ALL___IRQENABLE_SET access per field — Per-event interrupt enable bit vector. Write 1 to set (enable interrupt). Readout equal to corresponding _CLR register.
  [31] EOF rw — End of Frame Interrupt Write 0: No action Read 0: Interrupt disabled (masked) Read 1: Interrupt enabled Write 1: Enable interrupt
  [30] EOS rw — End of Slice Interrupt Write 0: No action Read 0: Interrupt disabled (masked) Read 1: Interrupt enabled Write 1: Enable interrupt
  [29] EOR rw — End of Frame Interrupt Write 0: No action Read 0: Interrupt disabled (masked) Read 1: Interrupt enabled Write 1: Enable interrupt
  [28] EOMB rw — End of Macroblock Interrupt Write 0: No action Read 0: Interrupt disabled (masked) Read 1: Interrupt enabled Write 1: Enable interrupt
  [21] HALT_IPCM rw — HALT_IPCM Interrupt Write 0: No action Read 0: Interrupt disabled (masked) Read 1: Interrupt enabled Write 1: Enable interrupt
  [20] HALT_SKIP rw — HALT_SKIP Interrupt Write 0: No action Read 0: Interrupt disabled (masked) Read 1: Interrupt enabled Write 1: Enable interrupt
  [19] HALT_Inter rw — HALT_Inter Interrupt Write 0: No action Read 0: Interrupt disabled (masked) Read 1: Interrupt enabled Write 1: Enable interrupt
  [18] HALT_I4x4 rw — HALT_I4x4 Interrupt Write 0: No action Read 0: Interrupt disabled (masked) Read 1: Interrupt enabled Write 1: Enable interrupt
  [17] HALT_I8x8 rw — HALT_I8x8 Interrupt Write 0: No action Read 0: Interrupt disabled (masked) Read 1: Interrupt enabled Write 1: Enable interrupt
  [16] HALT_I16x16 rw — HALT_I16x16 Interrupt Write 0: No action Read 0: Interrupt disabled (masked) Read 1: Interrupt enabled Write 1: Enable interrupt
  [1] AUTO_LD_DONE ro — Auto Load Done Interrupt Write 0: No action Read 0: Interrupt disabled (masked) Read 1: Interrupt enabled Write 1: Enable interrupt
  [0] EOP ro — End of Pipe Interrupt Write 0: No action Read 0: Interrupt disabled (masked) Read 1: Interrupt enabled Write 1: Enable interrupt
0x294 __ALL___IRQENABLE_CLR access per field — Per-event interrupt enable bit vector. Write 1 to clear (disable interrupt). Readout equal to corresponding _SET register.
  [31] EOF rw — End of Frame Interrupt Write 0: No action Read 0: Interrupt disabled (masked) Read 1: Interrupt enabled Write 1: Disable interrupt
  [30] EOS rw — End of Slice Interrupt Write 0: No action Read 0: Interrupt disabled (masked) Read 1: Interrupt enabled Write 1: Disable interrupt
  [29] EOR rw — End of Frame Interrupt Write 0: No action Read 0: Interrupt disabled (masked) Read 1: Interrupt enabled Write 1: Disable interrupt
  [28] EOMB rw — End of Macroblock Interrupt Write 0: No action Read 0: Interrupt disabled (masked) Read 1: Interrupt enabled Write 1: Disable interrupt
  [21] HALT_IPCM rw — HALT_IPCM Interrupt Write 0: No action Read 0: Interrupt disabled (masked) Read 1: Interrupt enabled Write 1: Disable interrupt
  [20] HALT_SKIP rw — HALT_Skip Interrupt Write 0: No action Read 0: Interrupt disabled (masked) Read 1: Interrupt enabled Write 1: Disable interrupt
  [19] HALT_Inter rw — HALT_Inter Interrupt Write 0: No action Read 0: Interrupt disabled (masked) Read 1: Interrupt enabled Write 1: Disable interrupt
  [18] HALT_I4x4 rw — HALT_I4x4 Interrupt Write 0: No action Read 0: Interrupt disabled (masked) Read 1: Interrupt enabled Write 1: Disable interrupt
  [17] HALT_I8x8 rw — HALT_I8x8 Interrupt Write 0: No action Read 0: Interrupt disabled (masked) Read 1: Interrupt enabled Write 1: Disable interrupt
  [16] HALT_I16x16 rw — HALT_I16x16 Interrupt Write 0: No action Read 0: Interrupt disabled (masked) Read 1: Interrupt enabled Write 1: Disable interrupt
  [1] AUTO_LD_DONE ro — Auto Load Done Interrupt Write 0: No action Read 0: Interrupt disabled (masked) Read 1: Interrupt enabled Write 1: Disable interrupt
  [0] EOP ro — End of Pipe Interrupt Write 0: No action Read 0: Interrupt disabled (masked) Read 1: Interrupt enabled Write 1: Disable interrupt
0x298 __ALL___IRQ_BLOCKING_CFG_INT0 access per field — Raw status of sources for interrupt INT0. Raw status is set even if the interrupt is not enabled; Write 1 to set the raw status (mostly for debug) The following is the behavior for read/write into each of the individual fields : Write 0: No action Write 1: Set event (for debug) Read 0: No event pending Read 1: Event pending
  [31] EOF rw — End of Frame Status
  [30] EOS rw — End of Slice Status
  [29] EOR rw — End of Frame Status
  [28] EOMB rw — End of Macroblock Status
  [21] HALT_IPCM rw — HALT_IPCM generated interupt Status
  [20] HALT_SKIP rw — HALT_SKIP generated interupt Status
  [19] HALT_Inter rw — HALT_Inter generated interupt Status
  [18] HALT_I4x4 rw — HALT_I4x4 generated interupt Status
  [17] HALT_I8x8 rw — HALT_I8x8 generated interupt Status
  [16] HALT_I16x16 rw — HALT_I16x16 generated interupt Status
  [1] AUTO_LD_DONE ro — Auto Load Done Status
  [0] EOP ro — End of Pipe Status
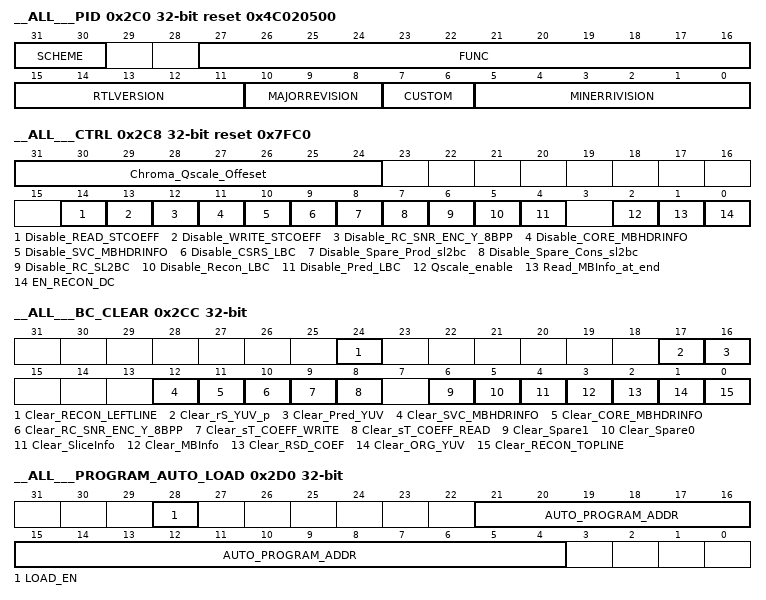
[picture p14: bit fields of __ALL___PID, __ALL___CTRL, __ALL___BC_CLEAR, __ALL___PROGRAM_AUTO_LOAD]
0x2C0 __ALL___PID ro reset 0x4C020500 — CALC5 PID register
  [31:30] SCHEME, [27:16] FUNC, [15:11] RTLVERSION, [10:8] MAJORREVISION, [7:6] CUSTOM, [5:0] MINERRIVISION
0x2C4 __ALL___HWA_ENABLE ro — CALC5 Enable Register
  [0] EN — CALC5 Module status and start bit Write [0] : Ignored Write [1] : Start CALC5 module Read [0] : Idle Read [1] : Busy
0x2C8 __ALL___CTRL access per field reset 0x7FC0 — CALC5 control register
  [31:24] Chroma_Qscale_Offeset ro — (Not Used)
  [14] Disable_READ_STCOEFF rw — Disable sl2bc for stcoeff read [0] : BC is active [1] : BC is inactive [default]
  [13] Disable_WRITE_STCOEFF rw — Disable sl2bc for stcoeff write [0] : BC is active [1] : BC is inactive [default]
  [12] Disable_RC_SNR_ENC_Y_8BPP rw — Disable sl2bc for rc luma 8bpp data transfer used by me in next layer [0] : BC is active [1] : BC is inactive [default]
  [11] Disable_CORE_MBHDRINFO rw — Disable sl2bc between CALC5 CORE and CALC5 DRM [0] : BC is active [1] : BC is inactive [default]
  [10] Disable_SVC_MBHDRINFO rw — Disable sl2bc between ME and CALC5 DRM [0] : BC is active [1] : BC is inactive [default]
  [9] Disable_CSRS_LBC rw — Disable LBC for CSRS YUV [0] : BC is active [1] : BC is inactive [default]
  [8] Disable_Spare_Prod_sl2bc rw — Producer Spare BC Status (Spare1_BC) [0] : Spare1 BC is active [1] : Spare1 BC is inactive [default]
  [7] Disable_Spare_Cons_sl2bc rw — Consumer Spare BC Status (Spare0_BC) [0] : Spare0 BC is active [1] : Spare0 BC is inactive [default]
  [6] Disable_RC_SL2BC rw — R/C SL2BC Status [0] : R/C SL2BC is active [1] : R/C SL2BC is inactive [Inter Pred Data is assumed to be 128] [Usage] In SVC-Encoder this bit shoud be set.
  [5] Disable_Recon_LBC rw — Recon Producer BC Signal Status [0] : BC signal for Recon are generated [1] : BC signal for Recon are not generated [Usage] In B-frame Encode, if LPF is power down. then this bit should be set.
  [4] Disable_Pred_LBC rw — Pred LBC Status [0] : Pred LBC is active [1] : Pred LBC is inactive [in Inter-MB Pred is assume to be 128] [Usage] In I-frame, if MC is power down. then this bit should be set.
  [2] Qscale_enable rw — This bit is effective only in ENCODER [1] : MB-Info will have "QScale" and not "qP" (CALC will internally derive qP) [0] : MB-Info will have "qP" and not "Qscale"
  [1] Read_MBInfo_at_end ro — [1] : MB-Infor of "N+1" will be read while computing "N" MB [0] : MB-Info (of "N") will be read befor startign computation of "N" MB
  [0] EN_RECON_DC rw — Enable LUMA-RECON DC generation clearning this bit will not clear the "RECON_DC_*" registers On clearign this bit the accumulation willnot happen in "RECON_DC_SUM" register
0x2CC __ALL___BC_CLEAR access per field — Initializes the BC (SL2BC/LBC) pointers to configured value (BC_START_PTR)
  [24] Clear_RECON_LEFTLINE rw — For Internal Buffere present in "W-Buf" Write 0: No action Write 1: initializing the BC pointers to "3" Read 1: initializing the BC pointers ongoing. Read 0:
  [17] Clear_rS_YUV_p rw — clear rs data from previous layer lbc (scaler) Write 0: No action Write 1: initializing the BC pointers to SL2_BC_START_PTR_RECON_TOPLINE Read 1: initializing the BC pointers ongoing. Read 0:
  [16] Clear_Pred_YUV rw — clear pred lbc between mc and calc core Write 0: No action Write 1: initializing the BC pointers to SL2_BC_START_PTR_RECON_TOPLINE Read 1: initializing the BC pointers ongoing. Read 0:
  [12] Clear_SVC_MBHDRINFO rw — clear mbinfo sl2bc between me and calc drm Write 0: No action Write 1: initializing the BC pointers to SL2_BC_START_PTR_RECON_TOPLINE Read 1: initializing the BC pointers ongoing. Read 0:
  [11] Clear_CORE_MBHDRINFO rw — clear mbinfo sl2bc between calc core and drm Write 0: No action Write 1: initializing the BC pointers to SL2_BC_START_PTR_RECON_TOPLINE Read 1: initializing the BC pointers ongoing. Read 0:
  [10] Clear_RC_SNR_ENC_Y_8BPP rw — clear rc 8bp data buffer used by me in next layer Write 0: No action Write 1: initializing the BC pointers to SL2_BC_START_PTR_RECON_TOPLINE Read 1: initializing the BC pointers ongoing. Read 0:
  [9] Clear_sT_COEFF_WRITE rw — clear stcoeff write buffer Write 0: No action Write 1: initializing the BC pointers to SL2_BC_START_PTR_RECON_TOPLINE Read 1: initializing the BC pointers ongoing. Read 0:
  [8] Clear_sT_COEFF_READ rw — clear stcoeff read buffer Write 0: No action Write 1: initializing the BC pointers to SL2_BC_START_PTR_RECON_TOPLINE Read 1: initializing the BC pointers ongoing. Read 0:
  [6] Clear_Spare1 ro — clear producer spare buffer Write 0: No action Write 1: initializing the BC pointers to SL2_BC_START_PTR_RECON_TOPLINE Read 1: initializing the BC pointers ongoing. Read 0:
  [5] Clear_Spare0 rw — clear consumer spare0 buffer Write 0: No action Write 1: initializing the BC pointers to SL2_BC_START_PTR_RECON_TOPLINE Read 1: initializing the BC pointers ongoing. Read 0:
  [4] Clear_SliceInfo rw — clear sliceinfo buffer Write 0: No action Write 1: initializing the BC pointers to SL2_BC_START_PTR_RECON_TOPLINE Read 1: initializing the BC pointers ongoing. Read 0:
  [3] Clear_MBInfo rw — clear mbinfo buffer Write 0: No action Write 1: initializing the BC pointers to SL2_BC_START_PTR_RECON_TOPLINE Read 1: initializing the BC pointers ongoing. Read 0:
  [2] Clear_RSD_COEF rw — clear residue data buffer Write 0: No action Write 1: initializing the BC pointers to SL2_BC_START_PTR_RECON_TOPLINE Read 1: initializing the BC pointers ongoing. Read 0:
  [1] Clear_ORG_YUV rw — clear original pixel buffer Write 0: No action Write 1: initializing the BC pointers to SL2_BC_START_PTR_RECON_TOPLINE Read 1: initializing the BC pointers ongoing. Read 0:
  [0] Clear_RECON_TOPLINE rw — clear recon topline buffer Write 0: No action Write 1: initializing the BC pointers to SL2_BC_START_PTR_RECON_TOPLINE Read 1: initializing the BC pointers ongoing. Read 0:
0x2D0 __ALL___PROGRAM_AUTO_LOAD access per field — Enables and specifies the SL2 location of the Auto Load MMR Image
  [28] LOAD_EN rw — Auto load enable. Write [0] : Ignored Write [1] : Autoload enable. Auto cleared once the Autoload is complete. Read [0] : Autoload complete Read [1] : Autoload ongoing
  [21:4] AUTO_PROGRAM_ADDR rw — Program Auto Load SL2 Base Address
0x2D4 __ALL___BC_IDLE access per field — Register to Idle the BCs
  [17] Idle_rS_YUV_p rw — Idle rs data from previous layer lbc (scaler) Write 0: No action Write 1: Disables BC Always ‘0’ is read
  [16] Idle_Pred_YUV rw — Idle pred lbc between mc and calc core Write 0: No action Write 1: Disables BC Always ‘0’ is read
  [12] Idle_SVC_MBHDRINFO rw — Idle mbinfo sl2bc between me and calc drm Write 0: No action Write 1: Disables BC Always ‘0’ is read
  [11] Idle_CORE_MBHDRINFO rw — Idle mbinfo sl2bc between calc core and drm Write 0: No action Write 1: Disables BC Always ‘0’ is read
  [10] Idle_RC_SNR_ENC_Y_8BPP rw — Idle rc 8bp data SL2BC used by me in next layer Write 0: No action Write 1: Disables BC Always ‘0’ is read
  [9] Idle_sT_COEFF_WRITE rw — Idle stcoeff write SL2BC Write 0: No action Write 1: Disables BC Always ‘0’ is read
  [8] Idle_sT_COEFF_READ rw — Idle stcoeff read SL2BC Write 0: No action Write 1: Disables BC Always ‘0’ is read
  [5] Idle_Cons_Spare0 rw — Idle consumer spare0 SL2BC Write 0: No action Write 1: Disables BC Always ‘0’ is read
  [4] Idle_SliceInfo rw — Idle sliceinfo Sl2BC Write 0: No action Write 1: Disables BC Always ‘0’ is read
  [3] Idle_MBInfo rw — Idles the mbinfo SL2BC Write 0: No action Write 1: Disables BC Always ‘0’ is read
  [2] Idle_RSD_COEF rw — Idles residue data SL2BC Write 0: No action Write 1: Disables BC Always ‘0’ is read
  [1] Idle_ORG_YUV rw — Idles the original pixel SL2BC Write 0: No action Write 1: Disables BC Always ‘0’ is read
  [0] Idle_RECON_TOPLINE rw — Idles the recon topline SL2BC Write 0: No action Write 1: Disables BC Always ‘0’ is read
0x2E0 __ALL___RECON_DC_MB ro — This Reg will accumulate DC only when "EN_RECON_DC" is set in CTRL MMR
  [7:0] DC_of_MB — This field hold the Average of all Luma-Recon of current MB
0x2E4 __ALL___RECON_DC_SUM ro — This Field may be used in Decode for Error Resilience Support This Reg will accumulate DC only when "EN_RECON_DC" is set in CTRL MMR)
  [31:0] SUM_of_DC — SUM of the DC of all the MB.. -> This Register will get cleared when MB-Info has "Row-Index and Column-Index equalt to Zero -> When Read .. It will return the Sum-of-DC till the latest complete MB
0x2E8 __ALL___HACK_CTRL access per field reset 0x3C320000 — HACK Control of CALC5
  [29:24] Disable_INV_Quant_sft rw — SFT used when Quant is disable [Default = -4]
  [21:16] Disable_FWD_Quant_sft rw — SFT used when Quant is disable [Default = -14]
  [15:14] Recon_Output rw — [0] : Normal Operation [1] : Inv_Transform [2] : Reserved [3] : Pred (Inter/Intra_16x16) (Assume CBP =0)
  [13:12] FWD_Trans_Input rw — [0] : Normal Operation [1] : Original (All MB-Type) [2] : Pred (Active for Inter "non-skip" and Intra_16x16) [3] : Zero (Force CBP to Zero for all MB-Type)
  [11] Disable_INV_Transform ro
  [10] Disable_INV_Quant rw — Disable Quant Matrix (normAdjust) generation Internallly "1" (unity scale) will be used. -> In Non-High profile it will give unity gain with default "Disable_FWD_Quant_sft = -14" -> In High Profile. it will do a dot product with matrix stored in W-Buf.
  [9] Disable_FWD_Quant rw — Disable Quant Matrix (normAdjust) generation -> Internallly "1" (unity scale) will be used. -> In Non-High profile it will give unity gain with default "Disable_FWD_Quant_sft = -14" -> In High Profile. it will do a dot product with matrix stored in W-Buf. -> FWD_SCALELIST_FORMAT MMR is don't care in this condition
  [8] Disable_FWD_Transform ro
  [6] Use_Pred_as_Org rw — Use Pred (MC-Output) as Original for I-Frame (Only in Encode) (MC-Shoudl be active in I-frame)
  [5] Inter_Pred_is_128 rw — Active only for Inter [0] : use MC-Ouput for Inter-Pred [1] : use 128 (0x80) for Inter-Pred
  [4] Bypass_RPF rw — [0] : Normal operation [1] : Bypass RefPix Filtering in Intra_8x8
  [0] Hack_enable rw — [1] : Hack Control is ACTIVE [0] : Other values in HACK MMR is don't care
0x300 __ALL___DBG_CAP ro reset 0xD00100 — This register contains the node revision code and all debug capacities of the module for HWa based
  [29] DBG_WP_DATA_SUP — Indicates if the WP resources has corresponding data qualification b0 – Not supported b1 – Data qualifiers are supported
  [28] DBG_OWN_SUP — Indicates if the HWA supports an module ownership. v2.0 and above. b0 – Not Supported b1 – Ownership supported
  [27] DBG_INDIRECT_SUP — Indicates if the HWA supports an indirect memory access port. v2.0 and above. b0 – Not Supported b1 – Indirect port supported
  [26] DBG_SWBP_SUP — Whether HWA Core supports SWBP or not. [0] – Not Supported [1] – Supported
  [25] Dbq_Reset_Sup — Whether HWA Core reset is supported or not which does not affect debug logic. b0 – Not Supported b1 – Supported
  [24] Sys_Exe_Req — Whether HWA Core Execution status and control is supported. b0 – Not Supported b1 – Supported
  [23] Trig_Output — b0 – Trigger Outputs are not supported b1 - Trigger Outputs are supported
  [22] Trig_Input — b0 - Trigger Inputs are not supported b1 - Trigger Inputs are supported
  [21:20] Trig_Chns — Number of Trigger Channels Supported b00 ------ No channels supported b01 ------ One channel supported b10 ------ Two channels supported Others ---- Reserved
  [19:16] Num_Cnts — The number of counter modules that exist. The registers supporting the counter modules must be implemented consecutively in the memory map
  [15:12] Num_Wps — The number of watchpoint modules that exist. The registers supporting the watchpoint modules must be implemented consecutively in the memory map
  [11:8] Num_Bps — The number of breakpoint modules that exist. The registers supporting the breakpoint modules must be implemented consecutively in the memory map.
  [7:0] RevNb_deprecated — Reserved – Write as 0
